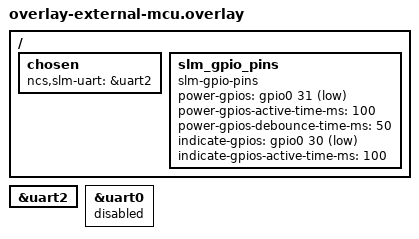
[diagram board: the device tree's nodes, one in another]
/*
 * Copyright (c) 2024 Nordic Semiconductor ASA
 *
 * SPDX-License-Identifier: LicenseRef-Nordic-5-Clause
 */

/ {
	chosen {
		ncs,slm-uart = &uart2;
	};
};

&uart2 {
	status = "okay";
};

/* uart0 is not needed if no logging is received there. */
&uart0 {
	status = "disabled";
};

/ {
	slm_gpio_pins: slm_gpio_pins {
		compatible = "slm-gpio-pins";
		power-gpios = <&gpio0 31 GPIO_ACTIVE_LOW>;
		power-gpios-active-time-ms = <100>;
		power-gpios-debounce-time-ms = <50>;
		indicate-gpios = <&gpio0 30 GPIO_ACTIVE_LOW>;
		indicate-gpios-active-time-ms = <100>;
	};
};
